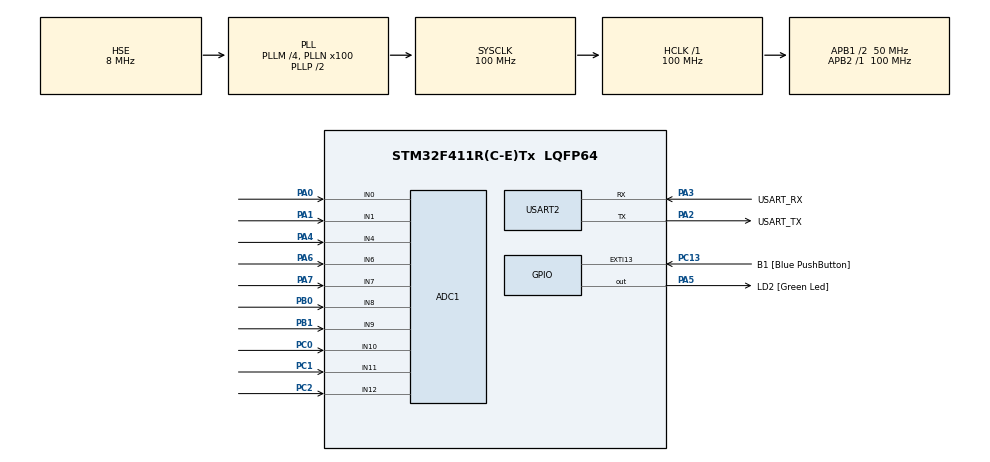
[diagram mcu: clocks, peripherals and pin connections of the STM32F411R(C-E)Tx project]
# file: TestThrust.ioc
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ADC1.Channel-0\#ChannelRegularConversion=ADC_CHANNEL_0
ADC1.Channel-1\#ChannelRegularConversion=ADC_CHANNEL_1
ADC1.Channel-2\#ChannelRegularConversion=ADC_CHANNEL_4
ADC1.Channel-3\#ChannelRegularConversion=ADC_CHANNEL_6
ADC1.Channel-4\#ChannelRegularConversion=ADC_CHANNEL_7
ADC1.Channel-5\#ChannelRegularConversion=ADC_CHANNEL_8
ADC1.Channel-6\#ChannelRegularConversion=ADC_CHANNEL_9
ADC1.Channel-7\#ChannelRegularConversion=ADC_CHANNEL_10
ADC1.Channel-8\#ChannelRegularConversion=ADC_CHANNEL_11
ADC1.Channel-9\#ChannelRegularConversion=ADC_CHANNEL_12
ADC1.NbrOfConversion=10
ADC1.NbrOfConversionFlag=1
ADC1.Rank-0\#ChannelRegularConversion=1
ADC1.Rank-1\#ChannelRegularConversion=2
ADC1.Rank-2\#ChannelRegularConversion=3
ADC1.Rank-3\#ChannelRegularConversion=4
ADC1.Rank-4\#ChannelRegularConversion=5
ADC1.Rank-5\#ChannelRegularConversion=6
ADC1.Rank-6\#ChannelRegularConversion=7
ADC1.Rank-7\#ChannelRegularConversion=8
ADC1.Rank-8\#ChannelRegularConversion=9
ADC1.Rank-9\#ChannelRegularConversion=10
ADC1.SamplingTime-0\#ChannelRegularConversion=ADC_SAMPLETIME_3CYCLES
ADC1.SamplingTime-1\#ChannelRegularConversion=ADC_SAMPLETIME_3CYCLES
ADC1.SamplingTime-2\#ChannelRegularConversion=ADC_SAMPLETIME_3CYCLES
ADC1.SamplingTime-3\#ChannelRegularConversion=ADC_SAMPLETIME_3CYCLES
ADC1.SamplingTime-4\#ChannelRegularConversion=ADC_SAMPLETIME_3CYCLES
ADC1.SamplingTime-5\#ChannelRegularConversion=ADC_SAMPLETIME_3CYCLES
ADC1.SamplingTime-6\#ChannelRegularConversion=ADC_SAMPLETIME_3CYCLES
ADC1.SamplingTime-7\#ChannelRegularConversion=ADC_SAMPLETIME_3CYCLES
ADC1.SamplingTime-8\#ChannelRegularConversion=ADC_SAMPLETIME_3CYCLES
ADC1.SamplingTime-9\#ChannelRegularConversion=ADC_SAMPLETIME_3CYCLES
ADC1.master=1
Dma.ADC1.0.Direction=DMA_PERIPH_TO_MEMORY
Dma.ADC1.0.FIFOMode=DMA_FIFOMODE_DISABLE
Dma.ADC1.0.Instance=DMA2_Stream0
Dma.ADC1.0.MemDataAlignment=DMA_MDATAALIGN_HALFWORD
Dma.ADC1.0.MemInc=DMA_MINC_ENABLE
Dma.ADC1.0.Mode=DMA_CIRCULAR
Dma.ADC1.0.PeriphDataAlignment=DMA_PDATAALIGN_HALFWORD
Dma.ADC1.0.PeriphInc=DMA_PINC_DISABLE
Dma.ADC1.0.Priority=DMA_PRIORITY_LOW
Dma.Request0=ADC1
Mcu.Family=STM32F4
Mcu.Name=STM32F411R(C-E)Tx
Mcu.Package=LQFP64
NVIC.DMA2_Stream0_IRQn=true\:0\:0\:false\:false\:true\:false\:true
NVIC.PriorityGroup=NVIC_PRIORITYGROUP_0
NVIC.TIM3_IRQn=true\:0\:0\:false\:false\:true\:true\:true
PA0-WKUP.Signal=ADCx_IN0
PA1.Signal=ADCx_IN1
PA13.GPIO_Label=TMS
PA13.Mode=Serial_Wire
PA13.Signal=SYS_JTMS-SWDIO
PA14.GPIO_Label=TCK
PA14.Mode=Serial_Wire
PA14.Signal=SYS_JTCK-SWCLK
PA2.GPIO_Label=USART_TX
PA2.Mode=Asynchronous
PA2.Signal=USART2_TX
PA3.GPIO_Label=USART_RX
PA3.Mode=Asynchronous
PA3.Signal=USART2_RX
PA4.Signal=ADCx_IN4
PA5.GPIO_Label=LD2 [Green Led]
PA5.Signal=GPIO_Output
PA6.Signal=ADCx_IN6
PA7.Signal=ADCx_IN7
PB0.Signal=ADCx_IN8
PB1.Signal=ADCx_IN9
PB3.GPIO_Label=SWO
PB3.Signal=SYS_JTDO-SWO
PC0.Signal=ADCx_IN10
PC1.Signal=ADCx_IN11
PC13-ANTI_TAMP.GPIO_Label=B1 [Blue PushButton]
PC13-ANTI_TAMP.GPIO_ModeDefaultEXTI=GPIO_MODE_IT_FALLING
PC13-ANTI_TAMP.Signal=GPXTI13
PC14-OSC32_IN.Mode=LSE-External-Oscillator
PC14-OSC32_IN.Signal=RCC_OSC32_IN
PC15-OSC32_OUT.Mode=LSE-External-Oscillator
PC15-OSC32_OUT.Signal=RCC_OSC32_OUT
PC2.Signal=ADCx_IN12
PH0\ -\ OSC_IN.Mode=HSE-External-Clock-Source
PH0\ -\ OSC_IN.Signal=RCC_OSC_IN
PH1\ -\ OSC_OUT.Mode=HSE-External-Clock-Source
PH1\ -\ OSC_OUT.Signal=RCC_OSC_OUT
ProjectManager.HeapSize=0x200
ProjectManager.StackSize=0x400
ProjectManager.TargetToolchain=STM32CubeIDE
RCC.48MHZClocksFreq_Value=50000000
RCC.AHBFreq_Value=100000000
RCC.APB1CLKDivider=RCC_HCLK_DIV2
RCC.APB1Freq_Value=50000000
RCC.APB1TimFreq_Value=100000000
RCC.APB2Freq_Value=100000000
RCC.APB2TimFreq_Value=100000000
RCC.CortexFreq_Value=100000000
RCC.FLatency-AdvancedSettings=FLASH_LATENCY_3
RCC.HCLKFreq_Value=100000000
RCC.HSE_VALUE=8000000
RCC.HSI_VALUE=16000000
RCC.PLLM=4
RCC.PLLN=100
RCC.PLLSourceVirtual=RCC_PLLSOURCE_HSE
RCC.SYSCLKFreq_VALUE=100000000
RCC.SYSCLKSource=RCC_SYSCLKSOURCE_PLLCLK
RCC.VCOOutputFreq_Value=200000000
SH.ADCx_IN0.0=ADC1_IN0,IN0
SH.ADCx_IN1.0=ADC1_IN1,IN1
SH.ADCx_IN10.0=ADC1_IN10,IN10
SH.ADCx_IN11.0=ADC1_IN11,IN11
SH.ADCx_IN12.0=ADC1_IN12,IN12
SH.ADCx_IN4.0=ADC1_IN4,IN4
SH.ADCx_IN6.0=ADC1_IN6,IN6
SH.ADCx_IN7.0=ADC1_IN7,IN7
SH.ADCx_IN8.0=ADC1_IN8,IN8
SH.ADCx_IN9.0=ADC1_IN9,IN9
TIM3.Channel-PWM\ Generation1\ No\ Output=TIM_CHANNEL_1
TIM3.Period=50000
TIM3.Prescaler=199
TIM3.Pulse-PWM\ Generation1\ No\ Output=1000
TIM3.TIM_MasterOutputTrigger=TIM_TRGO_UPDATE
USART2.VirtualMode=VM_ASYNC
VP_TIM3_VS_ClockSourceINT.Mode=Internal
VP_TIM3_VS_no_output1.Mode=PWM Generation1 No Output
board=NUCLEO-F411RE

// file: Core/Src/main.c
/* USER CODE BEGIN Header */
/**
  ******************************************************************************
  * @file           : main.c
  * @brief          : Main program body
  ******************************************************************************
  * @attention
  *
  * <h2><center>&copy; Copyright (c) 2022 STMicroelectronics.
  * All rights reserved.</center></h2>
  *
  * This software component is licensed by ST under BSD 3-Clause license,
  * the "License"; You may not use this file except in compliance with the
  * License. You may obtain a copy of the License at:
  *                        opensource.org/licenses/BSD-3-Clause
  *
  ******************************************************************************
  */
/* USER CODE END Header */
#include "main.h"
#include "adc.h"
#include "dma.h"
#include "tim.h"
#include "usart.h"
#include "gpio.h"

/* USER CODE BEGIN PV */
extern TIM_HandleTypeDef htim3;
/* USER CODE END PV */

void SystemClock_Config(void);

int main(void)
{

  /* MCU Configuration--------------------------------------------------------*/

  /* Reset of all peripherals, Initializes the Flash interface and the Systick. */
  HAL_Init();

  /* Configure the system clock */
  SystemClock_Config();

  /* Initialize all configured peripherals */
  MX_GPIO_Init();
  MX_USART2_UART_Init();
  MX_DMA_Init();
  MX_ADC1_Init();
  MX_TIM3_Init();
  /* USER CODE BEGIN 2 */
  HAL_TIM_PWM_Start_IT(&htim3,TIM_CHANNEL_1);
  /* USER CODE END 2 */

  /* Infinite loop */
  while (1)
  {

  }
}

void SystemClock_Config(void)
{
  RCC_OscInitTypeDef RCC_OscInitStruct = {0};
  RCC_ClkInitTypeDef RCC_ClkInitStruct = {0};

  /** Configure the main internal regulator output voltage
  */
  __HAL_RCC_PWR_CLK_ENABLE();
  __HAL_PWR_VOLTAGESCALING_CONFIG(PWR_REGULATOR_VOLTAGE_SCALE1);
  /** Initializes the RCC Oscillators according to the specified parameters
  * in the RCC_OscInitTypeDef structure.
  */
  RCC_OscInitStruct.OscillatorType = RCC_OSCILLATORTYPE_HSE;
  RCC_OscInitStruct.HSEState = RCC_HSE_BYPASS;
  RCC_OscInitStruct.PLL.PLLState = RCC_PLL_ON;
  RCC_OscInitStruct.PLL.PLLSource = RCC_PLLSOURCE_HSE;
  RCC_OscInitStruct.PLL.PLLM = 4;
  RCC_OscInitStruct.PLL.PLLN = 100;
  RCC_OscInitStruct.PLL.PLLP = RCC_PLLP_DIV2;
  RCC_OscInitStruct.PLL.PLLQ = 4;
  if (HAL_RCC_OscConfig(&RCC_OscInitStruct) != HAL_OK)
  {
    Error_Handler();
  }
  /** Initializes the CPU, AHB and APB buses clocks
  */
  RCC_ClkInitStruct.ClockType = RCC_CLOCKTYPE_HCLK|RCC_CLOCKTYPE_SYSCLK
                              |RCC_CLOCKTYPE_PCLK1|RCC_CLOCKTYPE_PCLK2;
  RCC_ClkInitStruct.SYSCLKSource = RCC_SYSCLKSOURCE_PLLCLK;
  RCC_ClkInitStruct.AHBCLKDivider = RCC_SYSCLK_DIV1;
  RCC_ClkInitStruct.APB1CLKDivider = RCC_HCLK_DIV2;
  RCC_ClkInitStruct.APB2CLKDivider = RCC_HCLK_DIV1;

  if (HAL_RCC_ClockConfig(&RCC_ClkInitStruct, FLASH_LATENCY_3) != HAL_OK)
  {
    Error_Handler();
  }
}

void Error_Handler(void)
{
  __disable_irq();
  while (1)
  {
  }
}

/************************ (C) COPYRIGHT STMicroelectronics *****END OF FILE****/
